VERSION ""

NS_ :

BS_:

BU_: IZZE_SG_4E5

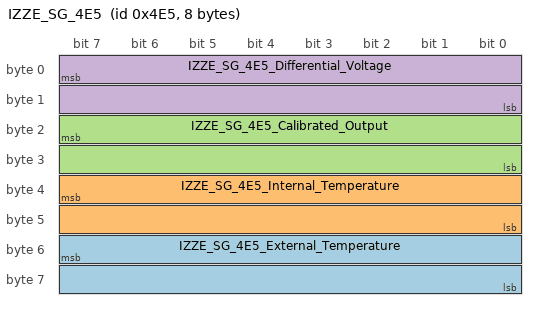
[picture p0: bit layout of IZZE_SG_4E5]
BO_ 1253 IZZE_SG_4E5: 8 IZZE_SG_4E5
 SG_ IZZE_SG_4E5_External_Temperature : 55|16@0- (0.1,0) [0|0] "C" Vector__XXX
 SG_ IZZE_SG_4E5_Internal_Temperature : 39|16@0- (0.1,0) [0|0] "C" Vector__XXX
 SG_ IZZE_SG_4E5_Calibrated_Output : 23|16@0- (0.1,0) [0|0] "F" Vector__XXX
 SG_ IZZE_SG_4E5_Differential_Voltage : 7|16@0- (1,0) [0|0] "µV" Vector__XXX

CM_ BO_ 1253 "Front right IZZE - raw voltage, calibrated output, temperatures";
BA_DEF_  "BusType" STRING ;
BA_DEF_DEF_  "BusType" "";
BA_ "BusType" "CAN";
